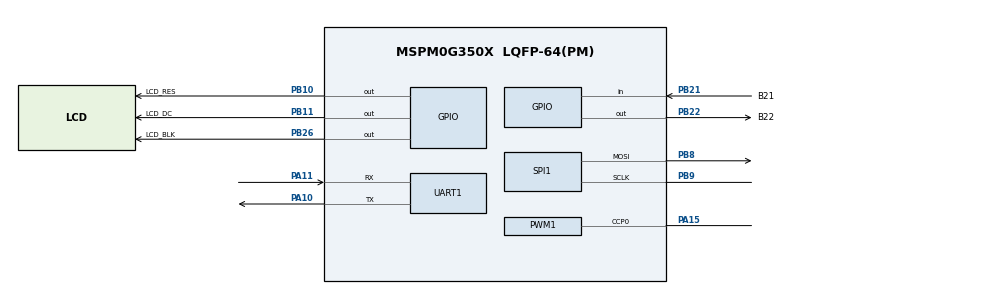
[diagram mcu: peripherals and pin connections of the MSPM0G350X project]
/**
 * @cliArgs --device "MSPM0G350X" --package "LQFP-64(PM)" --part "Default" --product "mspm0_sdk@1.30.00.03"
 * @versions {"tool":"1.19.0+3426"}
 */

/**
 * Import the modules used in this configuration.
 */
const GPIO    = scripting.addModule("/ti/driverlib/GPIO", {}, false);
const GPIO1   = GPIO.addInstance();
const GPIO2   = GPIO.addInstance();
const GPIO3   = GPIO.addInstance();
const GPIO4   = GPIO.addInstance();
const PWM     = scripting.addModule("/ti/driverlib/PWM", {}, false);
const PWM1    = PWM.addInstance();
const SPI     = scripting.addModule("/ti/driverlib/SPI", {}, false);
const SPI1    = SPI.addInstance();
const SYSCTL  = scripting.addModule("/ti/driverlib/SYSCTL");
const SYSTICK = scripting.addModule("/ti/driverlib/SYSTICK");
const TIMER   = scripting.addModule("/ti/driverlib/TIMER", {}, false);
const TIMER1  = TIMER.addInstance();
const TIMER2  = TIMER.addInstance();
const TIMER3  = TIMER.addInstance();
const UART    = scripting.addModule("/ti/driverlib/UART", {}, false);
const UART1   = UART.addInstance();

/**
 * Write custom configuration values to the imported modules.
 */
const divider9       = system.clockTree["UDIV"];
divider9.divideValue = 2;

const gate7  = system.clockTree["MFCLKGATE"];
gate7.enable = true;

const multiplier2         = system.clockTree["PLL_QDIV"];
multiplier2.multiplyValue = 4;

const mux4       = system.clockTree["EXHFMUX"];
mux4.inputSelect = "EXHFMUX_XTAL";

const mux8       = system.clockTree["HSCLKMUX"];
mux8.inputSelect = "HSCLKMUX_SYSPLL0";

const mux12       = system.clockTree["SYSPLLMUX"];
mux12.inputSelect = "zSYSPLLMUX_HFCLK";

const pinFunction4        = system.clockTree["HFXT"];
pinFunction4.inputFreq    = 40;
pinFunction4.enable       = true;
pinFunction4.HFCLKMonitor = true;
pinFunction4.HFXTStartup  = 10;

GPIO1.$name                               = "KEY";
GPIO1.port                                = "PORTB";
GPIO1.associatedPins[0].$name             = "B21";
GPIO1.associatedPins[0].direction         = "INPUT";
GPIO1.associatedPins[0].ioStructure       = "SD";
GPIO1.associatedPins[0].internalResistor  = "PULL_UP";
GPIO1.associatedPins[0].assignedPin       = "21";
GPIO1.associatedPins[0].polarity          = "RISE";
GPIO1.associatedPins[0].interruptEn       = true;
GPIO1.associatedPins[0].interruptPriority = "0";
GPIO1.associatedPins[0].pin.$assign       = "PB21";

const Board = scripting.addModule("/ti/driverlib/Board", {}, false);

GPIO2.$name                              = "LED";
GPIO2.port                               = "PORTB";
GPIO2.associatedPins[0].$name            = "B22";
GPIO2.associatedPins[0].ioStructure      = "SD";
GPIO2.associatedPins[0].internalResistor = "PULL_DOWN";
GPIO2.associatedPins[0].assignedPin      = "22";
GPIO2.associatedPins[0].pin.$assign      = "PB22";

GPIO3.$name                                       = "LCD_GPIO";
GPIO3.associatedPins.create(4);
GPIO3.associatedPins[0].$name                     = "LCD_RES";
GPIO3.associatedPins[0].ioStructure               = "SD";
GPIO3.associatedPins[0].initialValue              = "SET";
GPIO3.associatedPins[0].pin.$assign               = "PB10";
GPIO3.associatedPins[1].$name                     = "LCD_DC";
GPIO3.associatedPins[1].initialValue              = "SET";
GPIO3.associatedPins[1].ioStructure               = "SD";
GPIO3.associatedPins[1].pin.$assign               = "PB11";
GPIO3.associatedPins[2].$name                     = "LCD_CS";
GPIO3.associatedPins[2].initialValue              = "SET";
GPIO3.associatedPins[2].ioStructure               = "SD";
GPIO3.associatedPins[2].pin.$assignAllowConflicts = "PB14";
GPIO3.associatedPins[3].ioStructure               = "SD";
GPIO3.associatedPins[3].initialValue              = "SET";
GPIO3.associatedPins[3].$name                     = "LCD_BLK";
GPIO3.associatedPins[3].pin.$assign               = "PB26";

GPIO4.$name                          = "IIC_MPU6050";
GPIO4.associatedPins.create(2);
GPIO4.associatedPins[0].$name        = "MPU6050_SDA";
GPIO4.associatedPins[0].initialValue = "SET";
GPIO4.associatedPins[0].ioStructure  = "OD";
GPIO4.associatedPins[1].$name        = "MPU6050_SCL";
GPIO4.associatedPins[1].initialValue = "SET";
GPIO4.associatedPins[1].ioStructure  = "OD";

PWM1.$name                              = "PWM_LED";
PWM1.clockDivider                       = 8;
PWM1.clockPrescale                      = 10;
PWM1.timerStartTimer                    = true;
PWM1.ccIndex                            = [0];
PWM1.ccIndexCmpl                        = [0];
PWM1.peripheral.ccp0Pin.$assign         = "PA15";
PWM1.PWM_CHANNEL_0.$name                = "ti_driverlib_pwm_PWMTimerCC0";
PWM1.ccp0PinConfig.direction            = scripting.forceWrite("OUTPUT");
PWM1.ccp0PinConfig.hideOutputInversion  = scripting.forceWrite(false);
PWM1.ccp0PinConfig.onlyInternalResistor = scripting.forceWrite(false);
PWM1.ccp0PinConfig.passedPeripheralType = scripting.forceWrite("Digital");
PWM1.ccp0PinConfig.$name                = "ti_driverlib_gpio_GPIOPinGeneric2";
PWM1.ccp0Pin_cmplConfig.$name           = "ti_driverlib_gpio_GPIOPinGeneric3";

SPI1.$name                              = "LCD_SPI";
SPI1.direction                          = "PICO";
SPI1.targetBitRate                      = 32000000;
SPI1.frameFormat                        = "MOTO3";
SPI1.peripheral.$assign                 = "SPI1";
SPI1.peripheral.sclkPin.$assign         = "PB9";
SPI1.peripheral.mosiPin.$assign         = "PB8";
SPI1.sclkPinConfig.direction            = scripting.forceWrite("OUTPUT");
SPI1.sclkPinConfig.onlyInternalResistor = scripting.forceWrite(false);
SPI1.sclkPinConfig.passedPeripheralType = scripting.forceWrite("Digital");
SPI1.sclkPinConfig.$name                = "ti_driverlib_gpio_GPIOPinGeneric4";
SPI1.mosiPinConfig.direction            = scripting.forceWrite("OUTPUT");
SPI1.mosiPinConfig.hideOutputInversion  = scripting.forceWrite(false);
SPI1.mosiPinConfig.onlyInternalResistor = scripting.forceWrite(false);
SPI1.mosiPinConfig.passedPeripheralType = scripting.forceWrite("Digital");
SPI1.mosiPinConfig.$name                = "ti_driverlib_gpio_GPIOPinGeneric5";

SYSCTL.forceDefaultClkConfig = true;
SYSCTL.clockTreeEn           = true;

SYSTICK.periodEnable      = true;
SYSTICK.systickEnable     = true;
SYSTICK.interruptPriority = "0";
SYSTICK.period            = 16777215;

TIMER1.$name              = "TIMER_0";
TIMER1.timerMode          = "PERIODIC";
TIMER1.timerPeriod        = "1ms";
TIMER1.timerStartTimer    = true;
TIMER1.timerClkDiv        = 8;
TIMER1.timerClkPrescale   = 10;
TIMER1.interrupts         = ["ZERO"];
TIMER1.interruptPriority  = "0";
TIMER1.peripheral.$assign = "TIMA0";

TIMER2.$name = "Encoder_left";

TIMER3.$name     = "Encoder_right";
TIMER3.timerMode = "PERIODIC_UP";

UART1.targetBaudRate                   = 115200;
UART1.enabledInterrupts                = ["RX"];
UART1.interruptPriority                = "3";
UART1.$name                            = "UART_DEBUG";
UART1.peripheral.$assign               = "UART0";
UART1.peripheral.rxPin.$assign         = "PA11";
UART1.peripheral.txPin.$assign         = "PA10";
UART1.txPinConfig.direction            = scripting.forceWrite("OUTPUT");
UART1.txPinConfig.hideOutputInversion  = scripting.forceWrite(false);
UART1.txPinConfig.onlyInternalResistor = scripting.forceWrite(false);
UART1.txPinConfig.passedPeripheralType = scripting.forceWrite("Digital");
UART1.txPinConfig.$name                = "ti_driverlib_gpio_GPIOPinGeneric0";
UART1.rxPinConfig.hideOutputInversion  = scripting.forceWrite(false);
UART1.rxPinConfig.onlyInternalResistor = scripting.forceWrite(false);
UART1.rxPinConfig.passedPeripheralType = scripting.forceWrite("Digital");
UART1.rxPinConfig.$name                = "ti_driverlib_gpio_GPIOPinGeneric1";

/**
 * Pinmux solution for unlocked pins/peripherals. This ensures that minor changes to the automatic solver in a future
 * version of the tool will not impact the pinmux you originally saw.  These lines can be completely deleted in order to
 * re-solve from scratch.
 */
pinFunction4.peripheral.$suggestSolution           = "SYSCTL";
pinFunction4.peripheral.hfxInPin.$suggestSolution  = "PA5";
pinFunction4.peripheral.hfxOutPin.$suggestSolution = "PA6";
Board.peripheral.$suggestSolution                  = "DEBUGSS";
Board.peripheral.swclkPin.$suggestSolution         = "PA20";
Board.peripheral.swdioPin.$suggestSolution         = "PA19";
GPIO4.associatedPins[0].pin.$suggestSolution       = "PA1";
GPIO4.associatedPins[1].pin.$suggestSolution       = "PA0";
PWM1.peripheral.$suggestSolution                   = "TIMA1";
PWM1.peripheral.ccp0Pin_cmpl.$suggestSolution      = "PA8";
TIMER2.peripheral.$suggestSolution                 = "TIMG6";
TIMER3.peripheral.$suggestSolution                 = "TIMG0";
